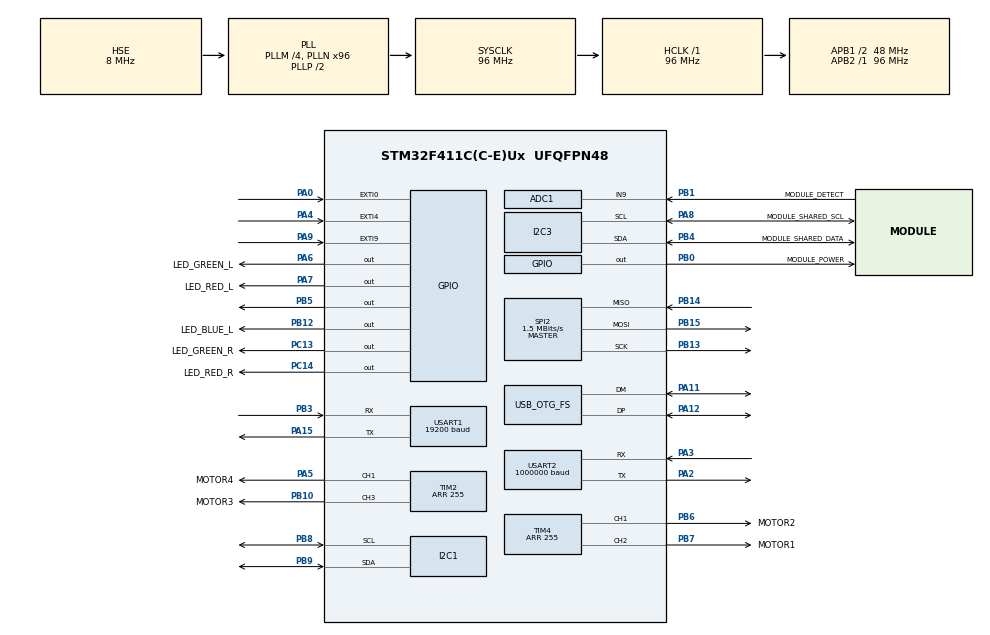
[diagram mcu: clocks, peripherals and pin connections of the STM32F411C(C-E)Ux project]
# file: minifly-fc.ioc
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ADC1.Channel-0\#ChannelRegularConversion=ADC_CHANNEL_9
ADC1.NbrOfConversionFlag=1
ADC1.Rank-0\#ChannelRegularConversion=1
ADC1.SamplingTime-0\#ChannelRegularConversion=ADC_SAMPLETIME_480CYCLES
ADC1.ScanConvMode=DISABLE
ADC1.master=1
Dma.ADC1.0.Direction=DMA_PERIPH_TO_MEMORY
Dma.ADC1.0.FIFOMode=DMA_FIFOMODE_DISABLE
Dma.ADC1.0.Instance=DMA2_Stream0
Dma.ADC1.0.MemDataAlignment=DMA_MDATAALIGN_HALFWORD
Dma.ADC1.0.MemInc=DMA_MINC_ENABLE
Dma.ADC1.0.Mode=DMA_CIRCULAR
Dma.ADC1.0.PeriphDataAlignment=DMA_PDATAALIGN_HALFWORD
Dma.ADC1.0.PeriphInc=DMA_PINC_DISABLE
Dma.ADC1.0.Priority=DMA_PRIORITY_LOW
Dma.I2C1_RX.1.Direction=DMA_PERIPH_TO_MEMORY
Dma.I2C1_RX.1.FIFOMode=DMA_FIFOMODE_DISABLE
Dma.I2C1_RX.1.Instance=DMA1_Stream0
Dma.I2C1_RX.1.MemDataAlignment=DMA_MDATAALIGN_BYTE
Dma.I2C1_RX.1.MemInc=DMA_MINC_ENABLE
Dma.I2C1_RX.1.Mode=DMA_NORMAL
Dma.I2C1_RX.1.PeriphDataAlignment=DMA_PDATAALIGN_BYTE
Dma.I2C1_RX.1.PeriphInc=DMA_PINC_DISABLE
Dma.I2C1_RX.1.Priority=DMA_PRIORITY_LOW
Dma.I2C3_RX.5.Direction=DMA_PERIPH_TO_MEMORY
Dma.I2C3_RX.5.FIFOMode=DMA_FIFOMODE_DISABLE
Dma.I2C3_RX.5.Instance=DMA1_Stream1
Dma.I2C3_RX.5.MemDataAlignment=DMA_MDATAALIGN_BYTE
Dma.I2C3_RX.5.MemInc=DMA_MINC_ENABLE
Dma.I2C3_RX.5.Mode=DMA_NORMAL
Dma.I2C3_RX.5.PeriphDataAlignment=DMA_PDATAALIGN_BYTE
Dma.I2C3_RX.5.PeriphInc=DMA_PINC_DISABLE
Dma.I2C3_RX.5.Priority=DMA_PRIORITY_LOW
Dma.Request0=ADC1
Dma.Request1=I2C1_RX
Dma.Request2=SPI2_RX
Dma.Request3=SPI2_TX
Dma.Request4=USART2_TX
Dma.Request5=I2C3_RX
Dma.SPI2_RX.2.Direction=DMA_PERIPH_TO_MEMORY
Dma.SPI2_RX.2.FIFOMode=DMA_FIFOMODE_DISABLE
Dma.SPI2_RX.2.Instance=DMA1_Stream3
Dma.SPI2_RX.2.MemDataAlignment=DMA_MDATAALIGN_BYTE
Dma.SPI2_RX.2.MemInc=DMA_MINC_ENABLE
Dma.SPI2_RX.2.Mode=DMA_NORMAL
Dma.SPI2_RX.2.PeriphDataAlignment=DMA_PDATAALIGN_BYTE
Dma.SPI2_RX.2.PeriphInc=DMA_PINC_DISABLE
Dma.SPI2_RX.2.Priority=DMA_PRIORITY_LOW
Dma.SPI2_TX.3.Direction=DMA_MEMORY_TO_PERIPH
Dma.SPI2_TX.3.FIFOMode=DMA_FIFOMODE_DISABLE
Dma.SPI2_TX.3.Instance=DMA1_Stream4
Dma.SPI2_TX.3.MemDataAlignment=DMA_MDATAALIGN_BYTE
Dma.SPI2_TX.3.MemInc=DMA_MINC_ENABLE
Dma.SPI2_TX.3.Mode=DMA_NORMAL
Dma.SPI2_TX.3.PeriphDataAlignment=DMA_PDATAALIGN_BYTE
Dma.SPI2_TX.3.PeriphInc=DMA_PINC_DISABLE
Dma.SPI2_TX.3.Priority=DMA_PRIORITY_LOW
Dma.USART2_TX.4.Direction=DMA_MEMORY_TO_PERIPH
Dma.USART2_TX.4.FIFOMode=DMA_FIFOMODE_DISABLE
Dma.USART2_TX.4.Instance=DMA1_Stream6
Dma.USART2_TX.4.MemDataAlignment=DMA_MDATAALIGN_BYTE
Dma.USART2_TX.4.MemInc=DMA_MINC_ENABLE
Dma.USART2_TX.4.Mode=DMA_NORMAL
Dma.USART2_TX.4.PeriphDataAlignment=DMA_PDATAALIGN_BYTE
Dma.USART2_TX.4.PeriphInc=DMA_PINC_DISABLE
Dma.USART2_TX.4.Priority=DMA_PRIORITY_LOW
FREERTOS.Tasks01=defaultTask,24,128,StartDefaultTask,Default,NULL,Dynamic,NULL,NULL
FREERTOS.configENABLE_FPU=1
FREERTOS.configTOTAL_HEAP_SIZE=30720
FREERTOS.configUSE_IDLE_HOOK=1
I2C1.I2C_Mode=I2C_Fast
I2C3.I2C_Mode=I2C_Fast
IWDG.Prescaler=IWDG_PRESCALER_32
IWDG.Reload=149
Mcu.Family=STM32F4
Mcu.Name=STM32F411C(C-E)Ux
Mcu.Package=UFQFPN48
NVIC.DMA1_Stream0_IRQn=true\:5\:0\:false\:false\:true\:true\:false\:true\:true
NVIC.DMA1_Stream1_IRQn=true\:5\:0\:false\:false\:true\:true\:false\:true\:true
NVIC.DMA1_Stream3_IRQn=true\:5\:0\:false\:false\:true\:true\:false\:true\:true
NVIC.DMA1_Stream4_IRQn=true\:5\:0\:false\:false\:true\:true\:false\:true\:true
NVIC.DMA1_Stream6_IRQn=true\:5\:0\:false\:false\:true\:true\:false\:true\:true
NVIC.DMA2_Stream0_IRQn=true\:5\:0\:false\:false\:true\:true\:false\:true\:true
NVIC.EXTI0_IRQn=true\:5\:0\:false\:false\:true\:true\:true\:true\:true
NVIC.EXTI4_IRQn=true\:5\:0\:false\:false\:true\:true\:true\:true\:true
NVIC.I2C1_ER_IRQn=true\:5\:0\:false\:false\:true\:true\:true\:true\:true
NVIC.I2C1_EV_IRQn=true\:5\:0\:false\:false\:true\:true\:true\:true\:true
NVIC.I2C3_ER_IRQn=true\:5\:0\:false\:false\:true\:true\:true\:true\:true
NVIC.I2C3_EV_IRQn=true\:5\:0\:false\:false\:true\:true\:true\:true\:true
NVIC.OTG_FS_IRQn=true\:5\:0\:true\:false\:true\:true\:false\:true\:true
NVIC.PriorityGroup=NVIC_PRIORITYGROUP_4
NVIC.TIM1_UP_TIM10_IRQn=true\:15\:0\:false\:false\:true\:false\:false\:true\:true
NVIC.TimeBase=TIM1_UP_TIM10_IRQn
NVIC.TimeBaseIP=TIM1
NVIC.USART1_IRQn=true\:5\:0\:false\:false\:true\:true\:true\:true\:true
NVIC.USART2_IRQn=true\:5\:0\:false\:false\:true\:true\:false\:true\:true
PA0-WKUP.GPIO_ModeDefaultEXTI=GPIO_MODE_IT_RISING_FALLING
PA0-WKUP.GPIO_PuPd=GPIO_PULLUP
PA0-WKUP.Signal=GPXTI0
PA11.Mode=Device_Only
PA11.Signal=USB_OTG_FS_DM
PA12.Mode=Device_Only
PA12.Signal=USB_OTG_FS_DP
PA13.Mode=Serial_Wire
PA13.Signal=SYS_JTMS-SWDIO
PA14.Mode=Serial_Wire
PA14.Signal=SYS_JTCK-SWCLK
PA15.Mode=Asynchronous
PA15.Signal=USART1_TX
PA2.Mode=Asynchronous
PA2.Signal=USART2_TX
PA3.Mode=Asynchronous
PA3.Signal=USART2_RX
PA4.GPIO_PuPd=GPIO_PULLDOWN
PA4.Signal=GPXTI4
PA5.GPIO_Label=MOTOR4
PA5.Signal=S_TIM2_CH1_ETR
PA6.GPIO_Label=LED_GREEN_L
PA6.GPIO_PuPd=GPIO_PULLDOWN
PA6.GPIO_Speed=GPIO_SPEED_FREQ_LOW
PA6.Signal=GPIO_Output
PA7.GPIO_Label=LED_RED_L
PA7.GPIO_PuPd=GPIO_PULLDOWN
PA7.Signal=GPIO_Output
PA8.GPIO_Label=MODULE_SHARED_SCL
PA8.Mode=I2C
PA8.Signal=I2C3_SCL
PA9.Signal=GPXTI9
PB0.GPIO_Label=MODULE_POWER
PB0.Signal=GPIO_Output
PB1.GPIO_Label=MODULE_DETECT
PB1.Signal=ADCx_IN9
PB10.GPIO_Label=MOTOR3
PB10.Signal=S_TIM2_CH3
PB12.GPIO_Label=LED_BLUE_L
PB12.GPIO_PuPd=GPIO_PULLUP
PB12.Signal=GPIO_Output
PB13.Mode=Full_Duplex_Master
PB13.Signal=SPI2_SCK
PB14.Mode=Full_Duplex_Master
PB14.Signal=SPI2_MISO
PB15.Mode=Full_Duplex_Master
PB15.Signal=SPI2_MOSI
PB3.Mode=Asynchronous
PB3.Signal=USART1_RX
PB4.GPIO_Label=MODULE_SHARED_DATA
PB4.Mode=I2C
PB4.Signal=I2C3_SDA
PB5.GPIO_PuPd=GPIO_NOPULL
PB5.Signal=GPIO_Output
PB6.GPIO_Label=MOTOR2
PB6.GPIO_PuPd=GPIO_PULLUP
PB6.GPIO_Speed=GPIO_SPEED_FREQ_LOW
PB6.Signal=S_TIM4_CH1
PB7.GPIO_Label=MOTOR1
PB7.GPIO_PuPd=GPIO_PULLUP
PB7.Signal=S_TIM4_CH2
PB8.Mode=I2C
PB8.Signal=I2C1_SCL
PB9.Mode=I2C
PB9.Signal=I2C1_SDA
PC13-ANTI_TAMP.GPIO_Label=LED_GREEN_R
PC13-ANTI_TAMP.GPIO_PuPd=GPIO_PULLDOWN
PC13-ANTI_TAMP.Signal=GPIO_Output
PC14-OSC32_IN.GPIO_Label=LED_RED_R
PC14-OSC32_IN.GPIO_PuPd=GPIO_PULLDOWN
PC14-OSC32_IN.Signal=GPIO_Output
PH0\ -\ OSC_IN.Mode=HSE-External-Oscillator
PH0\ -\ OSC_IN.Signal=RCC_OSC_IN
PH1\ -\ OSC_OUT.Mode=HSE-External-Oscillator
PH1\ -\ OSC_OUT.Signal=RCC_OSC_OUT
ProjectManager.HeapSize=0x200
ProjectManager.StackSize=0x400
ProjectManager.TargetToolchain=CMake
RCC.48MHZClocksFreq_Value=48000000
RCC.AHBFreq_Value=96000000
RCC.APB1CLKDivider=RCC_HCLK_DIV2
RCC.APB1Freq_Value=48000000
RCC.APB1TimFreq_Value=96000000
RCC.APB2Freq_Value=96000000
RCC.APB2TimFreq_Value=96000000
RCC.CortexFreq_Value=96000000
RCC.EnbaleCSS=true
RCC.HCLKFreq_Value=96000000
RCC.HSE_VALUE=8000000
RCC.HSI_VALUE=16000000
RCC.LSE_VALUE=32768
RCC.PLLM=4
RCC.PLLN=96
RCC.SYSCLKFreq_VALUE=96000000
RCC.SYSCLKSource=RCC_SYSCLKSOURCE_PLLCLK
RCC.VCOOutputFreq_Value=192000000
SH.ADCx_IN9.0=ADC1_IN9,IN9
SH.S_TIM2_CH1_ETR.0=TIM2_CH1,PWM Generation1 CH1
SH.S_TIM2_CH3.0=TIM2_CH3,PWM Generation3 CH3
SH.S_TIM4_CH1.0=TIM4_CH1,PWM Generation1 CH1
SH.S_TIM4_CH2.0=TIM4_CH2,PWM Generation2 CH2
SPI2.BaudRatePrescaler=SPI_BAUDRATEPRESCALER_32
SPI2.CalculateBaudRate=1.5 MBits/s
SPI2.Direction=SPI_DIRECTION_2LINES
SPI2.Mode=SPI_MODE_MASTER
SPI2.VirtualType=VM_MASTER
TIM2.Channel-PWM\ Generation1\ CH1=TIM_CHANNEL_1
TIM2.Channel-PWM\ Generation3\ CH3=TIM_CHANNEL_3
TIM2.Period=255
TIM4.Channel-PWM\ Generation1\ CH1=TIM_CHANNEL_1
TIM4.Channel-PWM\ Generation2\ CH2=TIM_CHANNEL_2
TIM4.Period=255
USART1.BaudRate=19200
USART1.VirtualMode=VM_ASYNC
USART2.BaudRate=1000000
USART2.VirtualMode=VM_ASYNC
USB_DEVICE.APP_RX_DATA_SIZE=512
USB_DEVICE.APP_TX_DATA_SIZE=512
USB_DEVICE.CLASS_NAME_FS=CDC
USB_DEVICE.USBD_MAX_NUM_INTERFACES=2
USB_DEVICE.VirtualMode=Cdc
USB_DEVICE.VirtualModeFS=Cdc_FS
USB_OTG_FS.VirtualMode=Device_Only
VP_FREERTOS_VS_CMSIS_V2.Mode=CMSIS_V2
VP_IWDG_VS_IWDG.Mode=IWDG_Activate
VP_SYS_VS_tim1.Mode=TIM1
VP_TIM2_VS_ClockSourceITR.Mode=TriggerSource_ITR0
VP_USB_DEVICE_VS_USB_DEVICE_CDC_FS.Mode=CDC_FS
board=custom

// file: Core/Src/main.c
/* USER CODE BEGIN Header */
/**
  ******************************************************************************
  * @file           : main.c
  * @brief          : Main program body
  ******************************************************************************
  * @attention
  *
  * Copyright (c) 2026 STMicroelectronics.
  * All rights reserved.
  *
  * This software is licensed under terms that can be found in the LICENSE file
  * in the root directory of this software component.
  * If no LICENSE file comes with this software, it is provided AS-IS.
  *
  ******************************************************************************
  */
/* USER CODE END Header */
#include "main.h"
#include "cmsis_os.h"
#include "adc.h"
#include "dma.h"
#include "i2c.h"
#include "iwdg.h"
#include "spi.h"
#include "tim.h"
#include "usart.h"
#include "usb_device.h"
#include "gpio.h"

/* USER CODE BEGIN Includes */
#include "app/app_boot.h"
/* USER CODE END Includes */

void SystemClock_Config(void);
void MX_FREERTOS_Init(void);

int main(void)
{

  /* MCU Configuration--------------------------------------------------------*/

  /* Reset of all peripherals, Initializes the Flash interface and the Systick. */
  HAL_Init();

  /* Configure the system clock */
  SystemClock_Config();

  /* Initialize all configured peripherals */
  MX_GPIO_Init();
  MX_DMA_Init();
  MX_ADC1_Init();
  MX_TIM2_Init();
  MX_USART1_UART_Init();
  MX_USART2_UART_Init();
  MX_I2C1_Init();
  MX_SPI2_Init();
  MX_TIM4_Init();
  MX_I2C3_Init();
  MX_IWDG_Init();
  /* USER CODE BEGIN 2 */
  // Initialize application-level subsystems before the RTOS scheduler starts
  app_boot_init();
  /* USER CODE END 2 */

  /* Init scheduler */
  osKernelInitialize();  /* Call init function for freertos objects (in cmsis_os2.c) */
  MX_FREERTOS_Init();

  /* Start scheduler */
  osKernelStart();

  /* We should never get here as control is now taken by the scheduler */

  /* Infinite loop */
  while (1)
  {

  }
}

void SystemClock_Config(void)
{
  RCC_OscInitTypeDef RCC_OscInitStruct = {0};
  RCC_ClkInitTypeDef RCC_ClkInitStruct = {0};

  /** Configure the main internal regulator output voltage
  */
  __HAL_RCC_PWR_CLK_ENABLE();
  __HAL_PWR_VOLTAGESCALING_CONFIG(PWR_REGULATOR_VOLTAGE_SCALE1);

  /** Initializes the RCC Oscillators according to the specified parameters
  * in the RCC_OscInitTypeDef structure.
  */
  RCC_OscInitStruct.OscillatorType = RCC_OSCILLATORTYPE_LSI|RCC_OSCILLATORTYPE_HSE;
  RCC_OscInitStruct.HSEState = RCC_HSE_ON;
  RCC_OscInitStruct.LSIState = RCC_LSI_ON;
  RCC_OscInitStruct.PLL.PLLState = RCC_PLL_ON;
  RCC_OscInitStruct.PLL.PLLSource = RCC_PLLSOURCE_HSE;
  RCC_OscInitStruct.PLL.PLLM = 4;
  RCC_OscInitStruct.PLL.PLLN = 96;
  RCC_OscInitStruct.PLL.PLLP = RCC_PLLP_DIV2;
  RCC_OscInitStruct.PLL.PLLQ = 4;
  if (HAL_RCC_OscConfig(&RCC_OscInitStruct) != HAL_OK)
  {
    Error_Handler();
  }

  /** Initializes the CPU, AHB and APB buses clocks
  */
  RCC_ClkInitStruct.ClockType = RCC_CLOCKTYPE_HCLK|RCC_CLOCKTYPE_SYSCLK
                              |RCC_CLOCKTYPE_PCLK1|RCC_CLOCKTYPE_PCLK2;
  RCC_ClkInitStruct.SYSCLKSource = RCC_SYSCLKSOURCE_PLLCLK;
  RCC_ClkInitStruct.AHBCLKDivider = RCC_SYSCLK_DIV1;
  RCC_ClkInitStruct.APB1CLKDivider = RCC_HCLK_DIV2;
  RCC_ClkInitStruct.APB2CLKDivider = RCC_HCLK_DIV1;

  if (HAL_RCC_ClockConfig(&RCC_ClkInitStruct, FLASH_LATENCY_3) != HAL_OK)
  {
    Error_Handler();
  }

  /** Enables the Clock Security System
  */
  HAL_RCC_EnableCSS();
}

void HAL_TIM_PeriodElapsedCallback(TIM_HandleTypeDef *htim)
{
  if (htim->Instance == TIM1)
  {
    HAL_IncTick();
  }
}

void Error_Handler(void)
{
  __disable_irq();
  while (1)
  {
  }
}

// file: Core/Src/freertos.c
/* USER CODE BEGIN Header */
/**
  ******************************************************************************
  * File Name          : freertos.c
  * Description        : Code for freertos applications
  ******************************************************************************
  * @attention
  *
  * Copyright (c) 2026 STMicroelectronics.
  * All rights reserved.
  *
  * This software is licensed under terms that can be found in the LICENSE file
  * in the root directory of this software component.
  * If no LICENSE file comes with this software, it is provided AS-IS.
  *
  ******************************************************************************
  */
/* USER CODE END Header */

#include "FreeRTOS.h"
#include "task.h"
#include "main.h"
#include "cmsis_os.h"

/* USER CODE BEGIN Includes */
#include "app/app_hooks.h"   // FreeRTOS hook callbacks (idle, stack overflow, etc.)
#include "app/app_tasks.h"   // Application task creation entry point
/* USER CODE END Includes */

/* Definitions for defaultTask */
osThreadId_t defaultTaskHandle;
const osThreadAttr_t defaultTask_attributes = {
  .name = "defaultTask",
  .stack_size = 128 * 4,
  .priority = (osPriority_t) osPriorityNormal,
};

void StartDefaultTask(void *argument);

extern void MX_USB_DEVICE_Init(void);
void MX_FREERTOS_Init(void); /* (MISRA C 2004 rule 8.1) */

/* Hook prototypes */
void vApplicationIdleHook(void);

/* USER CODE BEGIN 2 */
/**
 * @brief  FreeRTOS idle hook - called on every idle task iteration.
 * @note   Must never block. Delegates to app_idle_hook() for project-specific
 *         low-priority housekeeping (e.g. power management, watchdog feed).
 */
void vApplicationIdleHook( void )
{
   app_idle_hook();
}
/* USER CODE END 2 */

void MX_FREERTOS_Init(void) {

  /* Create the thread(s) */
  /* creation of defaultTask */
  defaultTaskHandle = osThreadNew(StartDefaultTask, NULL, &defaultTask_attributes);

  /* USER CODE BEGIN RTOS_THREADS */
  // Abort if CubeMX default task creation failed
  if (defaultTaskHandle == NULL)
  {
      Error_Handler();
  }
  // Create all application-level tasks (sensors, control, comm, etc.)
  app_tasks_create();
  /* USER CODE END RTOS_THREADS */

}

void StartDefaultTask(void *argument)
{
  /* init code for USB_DEVICE */
  MX_USB_DEVICE_Init();
  /* USER CODE BEGIN StartDefaultTask */
  // Default task: USB device init is done above; yield here as a placeholder.
  // Real work runs in app_tasks_create()'s dedicated task threads.
  for(;;)
  {
    osDelay(1);
  }
  /* USER CODE END StartDefaultTask */
}
